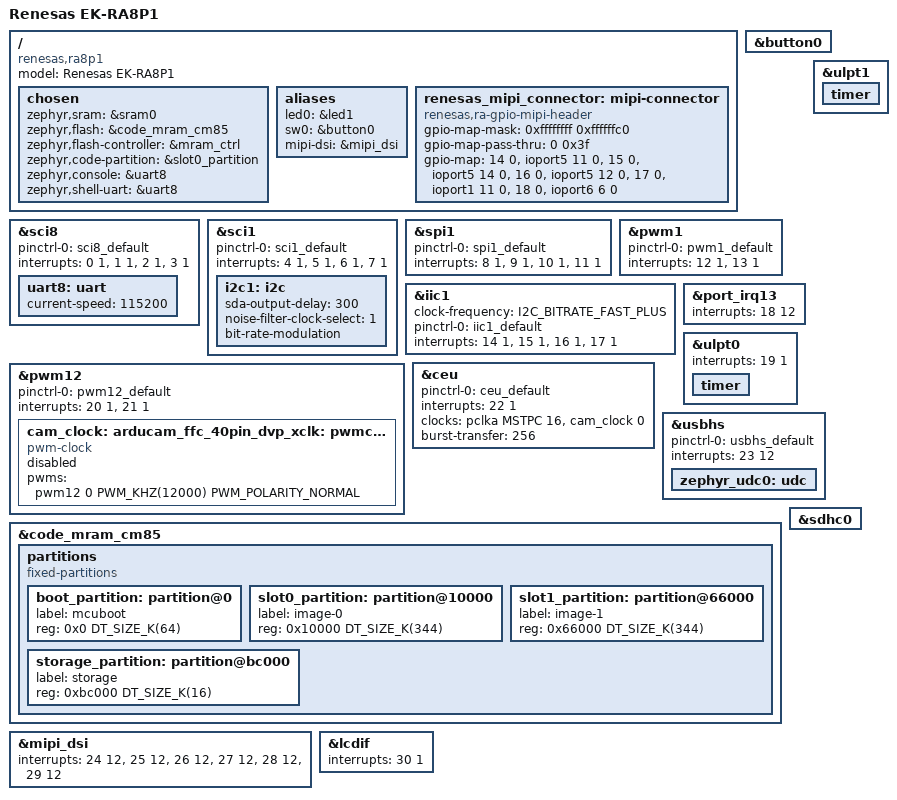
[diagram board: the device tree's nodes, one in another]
/*
 * Copyright (c) 2025 Renesas Electronics Corporation
 * SPDX-License-Identifier: Apache-2.0
 */

/dts-v1/;

#include <renesas/ra/ra8/r7ka8p1kflcac_cm85.dtsi>
#include <zephyr/dt-bindings/pwm/pwm.h>
#include "ek_ra8p1.dtsi"

/ {
	model = "Renesas EK-RA8P1";
	compatible = "renesas,ra8p1", "renesas,ra8";

	chosen {
		zephyr,sram = &sram0;
		zephyr,flash = &code_mram_cm85;
		zephyr,flash-controller = &mram_ctrl;
		zephyr,code-partition = &slot0_partition;
		zephyr,console = &uart8;
		zephyr,shell-uart = &uart8;
	};

	aliases {
		led0 = &led1;
		sw0 = &button0;
		mipi-dsi = &mipi_dsi;
	};

	renesas_mipi_connector: mipi-connector {
		compatible = "renesas,ra-gpio-mipi-header";
		#gpio-cells = <2>;
		gpio-map-mask = <0xffffffff 0xffffffc0>;
		gpio-map-pass-thru = <0 0x3f>;
		gpio-map = <14 0 &ioport5 11 0>, /* IIC_SDA */
			   <15 0 &ioport5 14 0>, /* DISP_BLEN */
			   <16 0 &ioport5 12 0>, /* IIC_SCL */
			   <17 0 &ioport1 11 0>, /* DISP_INT */
			   <18 0 &ioport6 6 0>;  /* DISP_RST */
	};
};

&button0 {
	status = "okay";
};

&sci8 {
	pinctrl-0 = <&sci8_default>;
	pinctrl-names = "default";
	interrupts = <0 1>, <1 1>, <2 1>, <3 1>;
	interrupt-names = "rxi", "txi", "tei", "eri";
	status = "okay";

	uart8: uart {
		current-speed = <115200>;
		status = "okay";
	};
};

&sci1 {
	pinctrl-0 = <&sci1_default>;
	pinctrl-names = "default";
	interrupts = <4 1>, <5 1>, <6 1>, <7 1>;
	interrupt-names = "rxi", "txi", "tei", "eri";

	i2c1: i2c {
		sda-output-delay = <300>;
		noise-filter-clock-select = <1>;
		bit-rate-modulation;
	};
};

&spi1 {
	pinctrl-0 = <&spi1_default>;
	pinctrl-names = "default";
	interrupts = <8 1>, <9 1>, <10 1>, <11 1>;
	interrupt-names = "rxi", "txi", "tei", "eri";
	status = "okay";
};

&pwm1 {
	pinctrl-0 = <&pwm1_default>;
	interrupts = <12 1>, <13 1>;
	interrupt-names = "gtioca", "overflow";
	pinctrl-names = "default";
	status = "okay";
};

&iic1 {
	#address-cells = <1>;
	#size-cells = <0>;
	clock-frequency = <I2C_BITRATE_FAST_PLUS>;
	pinctrl-0 = <&iic1_default>;
	pinctrl-names = "default";
	interrupts = <14 1>, <15 1>, <16 1>, <17 1>;
	interrupt-names = "rxi", "txi", "tei", "eri";
	status = "okay";
};

&port_irq13 {
	interrupts = <18 12>;
	status = "okay";
};

&ulpt0 {
	interrupts = <19 1>;
	interrupt-names = "ulpti";
	status = "okay";

	timer {
		status = "okay";
	};
};

&ulpt1 {
	status = "okay";

	timer {
		status = "okay";
	};
};

&pwm12 {
	pinctrl-0 = <&pwm12_default>;
	interrupts = <20 1>, <21 1>;
	interrupt-names = "gtioca", "overflow";
	pinctrl-names = "default";

	cam_clock: pwmclock {
		compatible = "pwm-clock";
		status = "disabled";
		#clock-cells = <1>;
		pwms = <&pwm12 0 PWM_KHZ(12000) PWM_POLARITY_NORMAL>;
	};
};

&ceu {
	pinctrl-0 = <&ceu_default>;
	pinctrl-names = "default";
	interrupts = <22 1>;
	interrupt-names = "ceui";
	clocks = <&pclka MSTPC 16>, <&cam_clock 0>;
	clock-names = "pclk", "cam-xclk";
	burst-transfer = <256>;
};

&usbhs {
	pinctrl-0 = <&usbhs_default>;
	interrupts = <23 12>;
	interrupt-names = "usbhs-ir";
	status = "okay";

	zephyr_udc0: udc {
		status = "okay";
	};
};

&code_mram_cm85 {
	partitions {
		compatible = "fixed-partitions";
		#address-cells = <1>;
		#size-cells = <1>;

		boot_partition: partition@0 {
			label = "mcuboot";
			reg = <0x0 DT_SIZE_K(64)>;
		};

		slot0_partition: partition@10000 {
			label = "image-0";
			reg = <0x10000 DT_SIZE_K(344)>;
		};

		slot1_partition: partition@66000 {
			label = "image-1";
			reg = <0x66000 DT_SIZE_K(344)>;
		};

		storage_partition: partition@bc000 {
			label = "storage";
			reg = <0xbc000 DT_SIZE_K(16)>;
		};
	};
};

&mipi_dsi {
	interrupts = <24 12>, <25 12>, <26 12>, <27 12>, <28 12>, <29 12>;
	interrupt-names = "sq0", "sq1", "vm", "rcv", "ferr", "ppi";
};

&lcdif {
	interrupts = <30 1>;
	interrupt-names = "line";
};

zephyr_lcdif: &lcdif {};

zephyr_mipi_dsi: &mipi_dsi {};

renesas_mipi_i2c: &iic1 {};

pmod_sd_shield: &sdhc0 {};

arducam_ffc_40pin_i2c: &iic1 {};

arducam_ffc_40pin_dvp_interface: &ceu {};

arducam_ffc_40pin_dvp_xclk: &cam_clock {};
